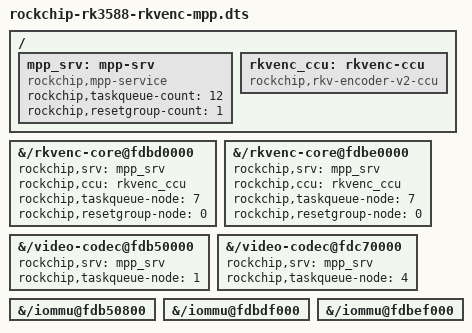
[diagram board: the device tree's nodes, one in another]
// SPDX-License-Identifier: (GPL-2.0+ OR MIT)
/*
 * DTS overlay for Rockchip RK3588 Video Hardware (Encoder & Decoder)
 */

/dts-v1/;
/plugin/;

/ {
    /* Fragment 0: Add new MPP service nodes to the root */
    fragment@0 {
        target-path = "/";
        __overlay__ {
            mpp_srv: mpp-srv {
                compatible = "rockchip,mpp-service";
                rockchip,taskqueue-count = <12>;
                rockchip,resetgroup-count = <1>;
                status = "okay";
            };

            rkvenc_ccu: rkvenc-ccu {
                compatible = "rockchip,rkv-encoder-v2-ccu";
                status = "okay";
            };
        };
    };

    /* Fragment 1: Enable Encoder Core 0 */
    fragment@1 {
        target-path = "/rkvenc-core@fdbd0000";
        __overlay__ {
            status = "okay";
            rockchip,srv = <&mpp_srv>;
            rockchip,ccu = <&rkvenc_ccu>;
            rockchip,taskqueue-node = <7>;
            rockchip,resetgroup-node = <0>;
        };
    };

    /* Fragment 2: Enable Encoder Core 1 */
    fragment@2 {
        target-path = "/rkvenc-core@fdbe0000";
        __overlay__ {
            status = "okay";
            rockchip,srv = <&mpp_srv>;
            rockchip,ccu = <&rkvenc_ccu>;
            rockchip,taskqueue-node = <7>;
            rockchip,resetgroup-node = <0>;
        };
    };

    /* Fragment 3: Enable VPU Decoder */
    fragment@3 {
        target-path = "/video-codec@fdb50000";
        __overlay__ {
            status = "okay";
            rockchip,srv = <&mpp_srv>;
            rockchip,taskqueue-node = <1>;
        };
    };

    /* Fragment 4: Enable AV1 Decoder */
    fragment@4 {
        target-path = "/video-codec@fdc70000";
        __overlay__ {
            status = "okay";
            rockchip,srv = <&mpp_srv>;
            rockchip,taskqueue-node = <4>;
        };
    };

    /* Fragments 5-7: Enable IOMMUs */
    fragment@5 { target-path = "/iommu@fdb50800"; __overlay__ { status = "okay"; }; };
    fragment@6 { target-path = "/iommu@fdbdf000"; __overlay__ { status = "okay"; }; };
    fragment@7 { target-path = "/iommu@fdbef000"; __overlay__ { status = "okay"; }; };
};
